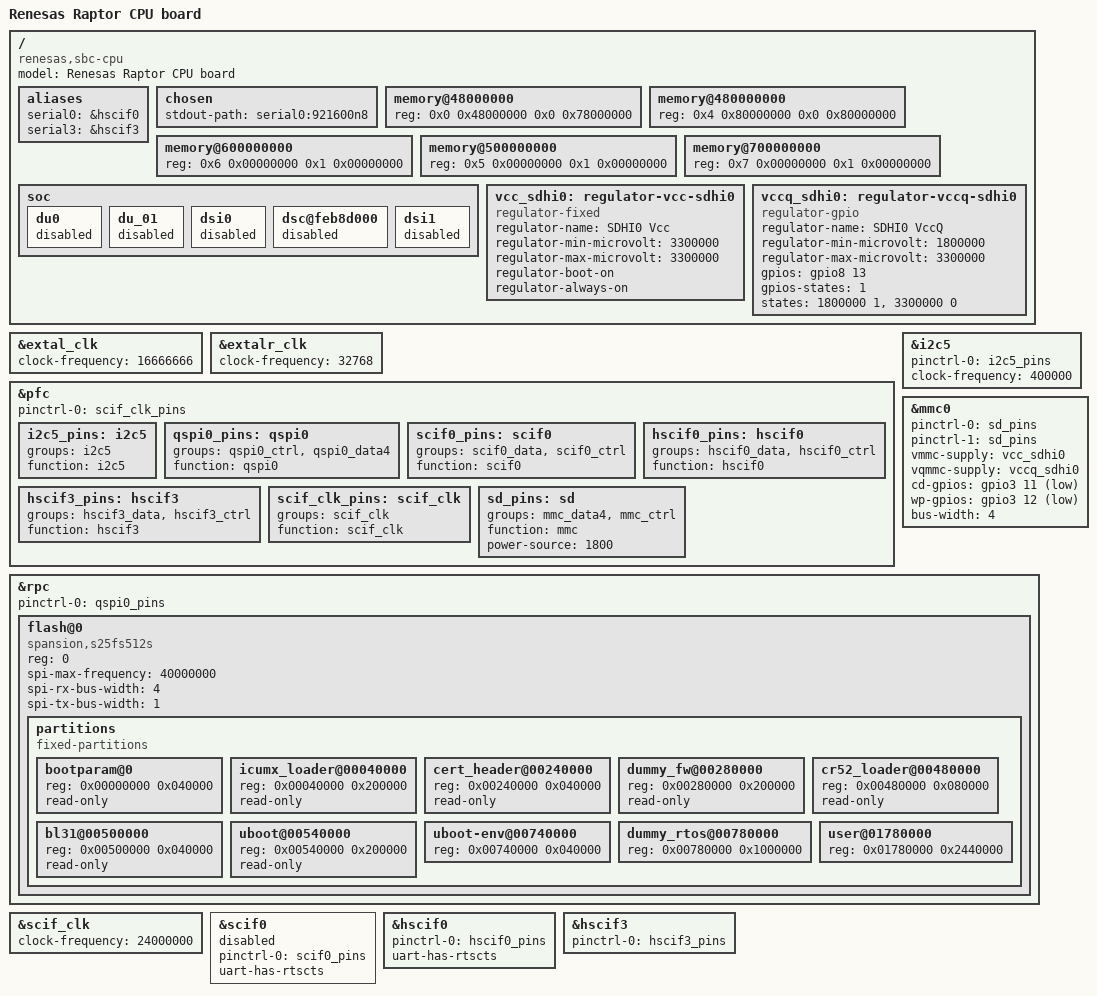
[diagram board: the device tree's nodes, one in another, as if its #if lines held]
// SPDX-License-Identifier: GPL-2.0
/*
 * Device Tree Source for the SBC CPU part
 *
 * Copyright (C) 2021 Renesas Electronics Corp.
 */

#include <dt-bindings/gpio/gpio.h>
#include <dt-bindings/input/input.h>

#include "r8a779g0.dtsi"
//#define PCBA_V1p0
//#define DDR_16G

/ {
	model = "Renesas Raptor CPU board";
	compatible = "renesas,sbc-cpu", "renesas,r8a779g0";

	aliases {
		serial0 = &hscif0;
		serial3 = &hscif3;
	};

	chosen {
		stdout-path = "serial0:921600n8";
	};

	memory@48000000 {
		device_type = "memory";
		/* first 128MB is reserved for secure area. */
		reg = <0x0 0x48000000 0x0 0x78000000>;
	};

	memory@480000000 {
		device_type = "memory";
		reg = <0x4 0x80000000 0x0 0x80000000>;
	};

	memory@600000000 {
		device_type = "memory";
		reg = <0x6 0x00000000 0x1 0x00000000>;
	};
#ifdef DDR_16G
	memory@500000000 {
		device_type = "memory";
		reg = <0x5 0x00000000 0x1 0x00000000>;
	};

	memory@700000000 {
		device_type = "memory";
		reg = <0x7 0x00000000 0x1 0x00000000>;
	};

#endif
	soc: soc {
		du0 {
			status = "disabled";
		};

		du_01 {
			status = "disabled";
		};

		dsi0 {
			status = "disabled";
		};

		dsc@feb8d000 {
			status = "disabled";
		};

		dsi1 {
			status = "disabled";
		};
	};

	vcc_sdhi0: regulator-vcc-sdhi0 {
		compatible = "regulator-fixed";

		regulator-name = "SDHI0 Vcc";
		regulator-min-microvolt = <3300000>;
		regulator-max-microvolt = <3300000>;

		regulator-boot-on;
		regulator-always-on;
	};

	vccq_sdhi0: regulator-vccq-sdhi0 {
		compatible = "regulator-gpio";

		regulator-name = "SDHI0 VccQ";
		regulator-min-microvolt = <1800000>;
		regulator-max-microvolt = <3300000>;

		gpios = <&gpio8 13 GPIO_ACTIVE_HIGH>;
#ifdef PCBA_V1p0
		gpios-states = <1>;
		states = <1800000 1>, <3300000 0>;
#else
		gpios-states = <0>;
		states = <1800000 0>, <3300000 1>;
#endif
	};
};

&extal_clk {
	clock-frequency = <16666666>;
};

&extalr_clk {
	clock-frequency = <32768>;
};

&pfc {
	pinctrl-0 = <&scif_clk_pins>;
	pinctrl-names = "default";

	

	i2c5_pins: i2c5 {
		groups = "i2c5";
		function = "i2c5";
	};

	qspi0_pins: qspi0 {
		groups = "qspi0_ctrl", "qspi0_data4";
		function = "qspi0";
	};

	scif0_pins: scif0 {
		groups = "scif0_data", "scif0_ctrl";
		function = "scif0";
	};

	hscif0_pins: hscif0 {
		groups = "hscif0_data", "hscif0_ctrl";
		function = "hscif0";
	};

	hscif3_pins: hscif3 {
		groups = "hscif3_data", "hscif3_ctrl";
		function = "hscif3";
	};      
	

	scif_clk_pins: scif_clk {
		groups = "scif_clk";
		function = "scif_clk";
	};

	sd_pins: sd {
		groups = "mmc_data4", "mmc_ctrl";
		function = "mmc";
		power-source = <1800>;
	};
};

/*
 * I2C5 Function :
 * enable I2C5 for PMIC
 */
&i2c5 {
	pinctrl-0 = <&i2c5_pins>;
	pinctrl-names = "default";

	status = "okay";
	clock-frequency = <400000>;
};

/*
 * SD Function : 
 * define pad power, flash power, speed and bus width 
 */
&mmc0 {
	pinctrl-0 = <&sd_pins>;
	pinctrl-1 = <&sd_pins>;
	pinctrl-names = "default", "state_uhs";

	vmmc-supply = <&vcc_sdhi0>;
	vqmmc-supply = <&vccq_sdhi0>;
	cd-gpios = <&gpio3 11 GPIO_ACTIVE_LOW>;
	wp-gpios = <&gpio3 12 GPIO_ACTIVE_LOW>;
	bus-width = <4>;
	status = "okay";
};

/*
 * SPIFlash Function : 
 * define bus width and partitions 
 */
&rpc {
	pinctrl-0 = <&qspi0_pins>;
	pinctrl-names = "default";
	status = "okay";
	
	flash@0 {
		compatible = "spansion,s25fs512s", "jedec,spi-nor";
		reg = <0>;
		spi-max-frequency = <40000000>;
		spi-rx-bus-width = <4>;
		spi-tx-bus-width = <1>;

		partitions {
			compatible = "fixed-partitions";
			#address-cells = <1>;
			#size-cells = <1>;

			bootparam@0 {
				reg = <0x00000000 0x040000>;
				read-only;
			};
			icumx_loader@00040000 {
				reg = <0x00040000 0x200000>;
				read-only;
			};
			cert_header@00240000 {
				reg = <0x00240000 0x040000>;
				read-only;
			};
			dummy_fw@00280000 {
				reg = <0x00280000 0x200000>;
				read-only;
			};
			cr52_loader@00480000 {
				reg = <0x00480000 0x080000>;
				read-only;
			};
			bl31@00500000 {
				reg = <0x00500000 0x040000>;
				read-only;
			};
			uboot@00540000 {
				reg = <0x00540000 0x200000>;
				read-only;
			};
			uboot-env@00740000 {
				reg = <0x00740000 0x040000>;
//				read-only;
			};
			dummy_rtos@00780000 {
				reg = <0x00780000 0x1000000>;
			};
			user@01780000 {
				reg = <0x01780000 0x2440000>;
			};
		};
	};
};

/*
 * Serial Console Function : 
 * enable hscif0 and disable scif0 
 */
&scif_clk {
	clock-frequency = <24000000>;
};

&scif0 {
	pinctrl-0 = <&scif0_pins>;
	pinctrl-names = "default";

	uart-has-rtscts;
	/* Please use exclusively to the hscif0 node */
	status = "disabled";
};

&hscif0 {
	pinctrl-0 = <&hscif0_pins>;
	pinctrl-names = "default";

	uart-has-rtscts;
	/* Please use exclusively to the scif0 node */
	status = "okay";
};

&hscif3 {
       pinctrl-0 = <&hscif3_pins>;
       pinctrl-names = "default";

//       uart-has-rtscts;

       status = "okay";
};

